# MKL28T7_CORE1 register map
Vendor: Freescale Semiconductor, Inc.; Series: Kinetis_L; File version: 1.6
CPU: CM0PLUS r0p0, little endian, no MPU, no FPU, VTOR, 2 interrupt priority bits
Registers are 32-bit, read-write, reset 0x0 unless marked. A register's access mark holds for its fields unless they carry their own. Offsets are from the block's base; [hi:lo] are bit positions; {n}, {i} and the like mark numbered series; 'fields as' and 'values as' point back to an identical list.

## PCC0
Base 0x4007A000
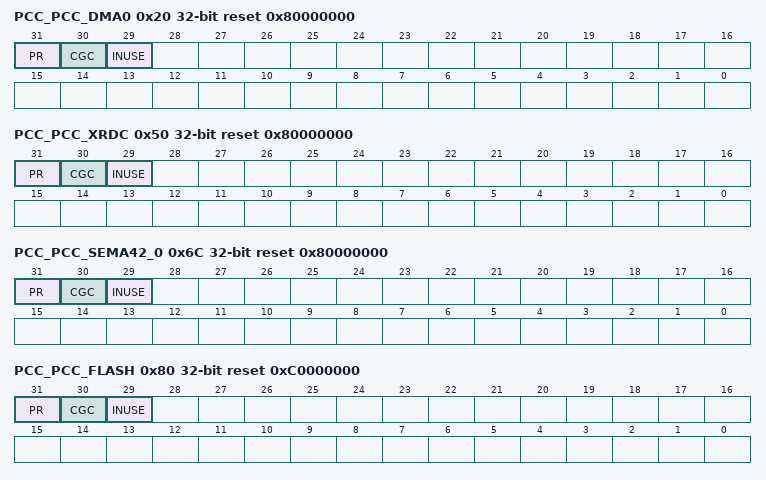
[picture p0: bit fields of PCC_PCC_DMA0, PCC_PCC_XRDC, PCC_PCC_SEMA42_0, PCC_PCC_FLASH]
0x20 PCC_PCC_DMA0 reset 0x80000000 — PCC_DMA0 Register
  [31] PR ro — Enable
    0=Peripheral is not present; 1=Peripheral is present
  [30] CGC — Clock Gate Control
    0=Clock disabled; 1=Clock enabled
  [29] INUSE ro — Clock Gate Control
    0=Another core is not using this peripheral; 1=Another core is using this peripheral. Software cannot modify the existing clocking configuration.
0x50 PCC_PCC_XRDC reset 0x80000000 — PCC_XRDC Register
  fields as PCC_PCC_DMA0
0x6C PCC_PCC_SEMA42_0 reset 0x80000000 — PCC_SEMA42_0 Register
  fields as PCC_PCC_DMA0
0x80 PCC_PCC_FLASH reset 0xC0000000 — PCC_FLASH Register
  fields as PCC_PCC_DMA0
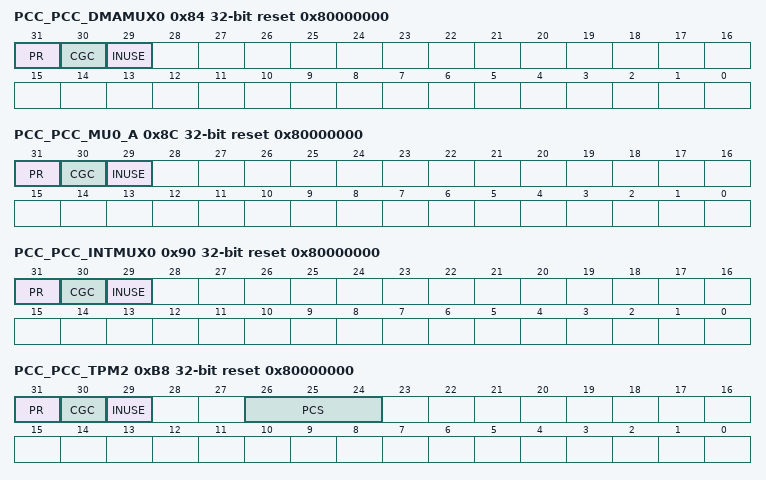
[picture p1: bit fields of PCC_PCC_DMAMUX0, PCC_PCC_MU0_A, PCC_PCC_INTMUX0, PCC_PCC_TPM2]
0x84 PCC_PCC_DMAMUX0 reset 0x80000000 — PCC_DMAMUX0 Register
  fields as PCC_PCC_DMA0
0x8C PCC_PCC_MU0_A reset 0x80000000 — PCC_MU0_A Register
  fields as PCC_PCC_DMA0
0x90 PCC_PCC_INTMUX0 reset 0x80000000 — PCC_INTMUX0 Register
  fields as PCC_PCC_DMA0
0xB8 PCC_PCC_TPM2 reset 0x80000000 — PCC_TPM2 Register
  [31] PR ro — Enable
    0=Peripheral is not present; 1=Peripheral is present
  [30] CGC — Clock Gate Control
    0=Clock disabled; 1=Clock enabled
  [29] INUSE ro — Clock Gate Control
    values as PCC_PCC_DMA0.INUSE
  [26:24] PCS — Peripheral Clock Source Select
    0=Clock is off (or test clock is enabled); 1=OSCCLK - System Oscillator Bus Clock(scg_sosc_slow_clk); 2=SCGIRCLK - Slow IRC Clock(scg_sirc_slow_clk), (maximum is 8MHz); 3=SCGFIRCLK - Fast IRC Clock(scg_firc_slow_clk), (maximum is 48MHz); 6=SCGPCLK System PLL clock (scg_spll_slow_clk)
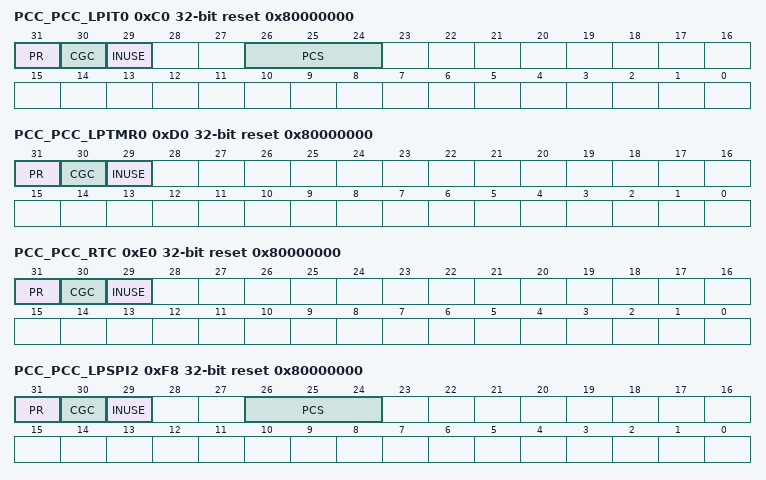
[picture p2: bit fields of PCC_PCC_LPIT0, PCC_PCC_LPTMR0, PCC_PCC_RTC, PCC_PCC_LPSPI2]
0xC0 PCC_PCC_LPIT0 reset 0x80000000 — PCC_LPIT0 Register
  fields as PCC_PCC_TPM2
0xD0 PCC_PCC_LPTMR0 reset 0x80000000 — PCC_LPTMR0 Register
  fields as PCC_PCC_DMA0
0xE0 PCC_PCC_RTC reset 0x80000000 — PCC_RTC Register
  fields as PCC_PCC_DMA0
0xF8 PCC_PCC_LPSPI2 reset 0x80000000 — PCC_LPSPI2 Register
  fields as PCC_PCC_TPM2
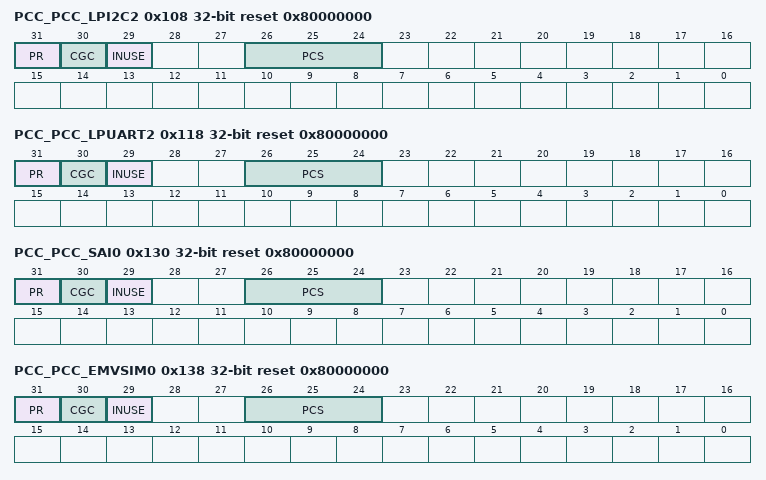
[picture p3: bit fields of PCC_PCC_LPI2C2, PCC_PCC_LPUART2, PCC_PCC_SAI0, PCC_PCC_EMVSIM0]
0x108 PCC_PCC_LPI2C2 reset 0x80000000 — PCC_LPI2C2 Register
  fields as PCC_PCC_TPM2
0x118 PCC_PCC_LPUART2 reset 0x80000000 — PCC_LPUART2 Register
  fields as PCC_PCC_TPM2
0x130 PCC_PCC_SAI0 reset 0x80000000 — PCC_SAI0 Register
  [31] PR ro — Enable
    0=Peripheral is not present; 1=Peripheral is present
  [30] CGC — Clock Gate Control
    0=Clock disabled; 1=Clock enabled
  [29] INUSE ro — Clock Gate Control
    values as PCC_PCC_DMA0.INUSE
  [26:24] PCS — Peripheral Clock Source Select
    0=Clock is off (or test clock is enabled) An external clock can be enabled for this peripheral; 1=OSCCLK - System Oscillator Bus Clock(scg_sosc_slow_clk); 2=SCGIRCLK - Slow IRC Clock(scg_sirc_slow_clk), (maximum is 8MHz); 3=SCGFIRCLK - Fast IRC Clock(scg_firc_slow_clk), (maximum is 48MHz); 6=SCGPCLK System PLL clock (scg_spll_slow_clk)
0x138 PCC_PCC_EMVSIM0 reset 0x80000000 — PCC_EMVSIM0 Register
  fields as PCC_PCC_TPM2
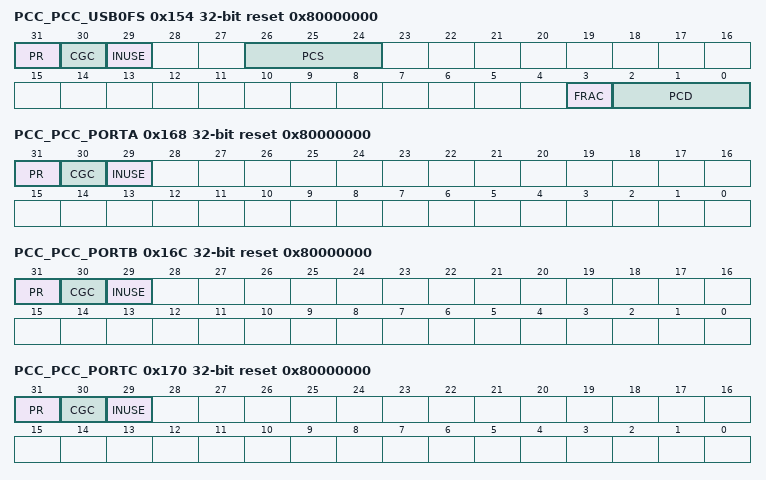
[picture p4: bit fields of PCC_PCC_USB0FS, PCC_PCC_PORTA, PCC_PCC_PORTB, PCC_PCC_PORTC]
0x154 PCC_PCC_USB0FS reset 0x80000000 — PCC_USB0FS Register
  [31] PR ro — Enable
    0=Peripheral is not present; 1=Peripheral is present
  [30] CGC — Clock Gate Control
    0=Clock disabled; 1=Clock enabled
  [29] INUSE ro — Clock Gate Control
    values as PCC_PCC_DMA0.INUSE
  [26:24] PCS — Peripheral Clock Source Select
    0=Clock is off (or test clock is enabled) An external clock can be enabled for this peripheral; 1=OSCCLK - System Oscillator Platform Clock(scg_sosc_plat_clk); 2=SCGIRCLK - Slow IRC Clock(scg_sirc_plat_clk), (maximum is 8MHz); 3=SCGFIRCLK - Fast IRC Clock(scg_firc_plat_clk), (maximum is 48MHz); 6=SCGPCLK System PLL clock (scg_spll_plat_clk)
  [3] FRAC — Peripheral Clock Divider Fraction
    0=Fractional value is 0; 1=Fractional value is 1
  [2:0] PCD — Peripheral Clock Divider Select
    0=Divide by 1 (pass-through, no clock divide); {v}=Divide by {v+1} (v=1..7)
0x168 PCC_PCC_PORTA reset 0x80000000 — PCC_PORTA Register
  fields as PCC_PCC_DMA0
0x16C PCC_PCC_PORTB reset 0x80000000 — PCC_PORTB Register
  fields as PCC_PCC_DMA0
0x170 PCC_PCC_PORTC reset 0x80000000 — PCC_PORTC Register
  fields as PCC_PCC_DMA0
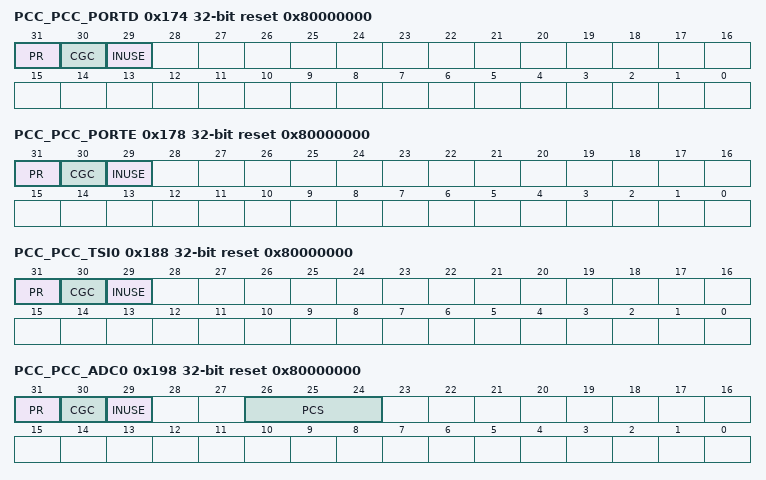
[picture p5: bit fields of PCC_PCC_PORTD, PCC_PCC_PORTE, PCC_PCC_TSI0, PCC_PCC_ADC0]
0x174 PCC_PCC_PORTD reset 0x80000000 — PCC_PORTD Register
  fields as PCC_PCC_DMA0
0x178 PCC_PCC_PORTE reset 0x80000000 — PCC_PORTE Register
  fields as PCC_PCC_DMA0
0x188 PCC_PCC_TSI0 reset 0x80000000 — PCC_TSI0 Register
  fields as PCC_PCC_DMA0
0x198 PCC_PCC_ADC0 reset 0x80000000 — PCC_ADC0 Register
  fields as PCC_PCC_TPM2
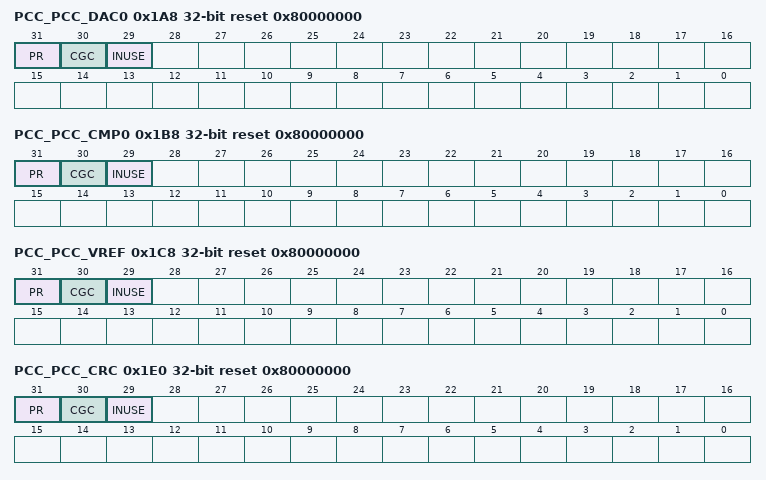
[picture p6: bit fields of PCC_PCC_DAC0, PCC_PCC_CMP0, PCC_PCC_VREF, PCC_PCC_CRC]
0x1A8 PCC_PCC_DAC0 reset 0x80000000 — PCC_DAC0 Register
  fields as PCC_PCC_DMA0
0x1B8 PCC_PCC_CMP0 reset 0x80000000 — PCC_CMP0 Register
  fields as PCC_PCC_DMA0
0x1C8 PCC_PCC_VREF reset 0x80000000 — PCC_VREF Register
  fields as PCC_PCC_DMA0
0x1E0 PCC_PCC_CRC reset 0x80000000 — PCC_CRC Register
  fields as PCC_PCC_DMA0
